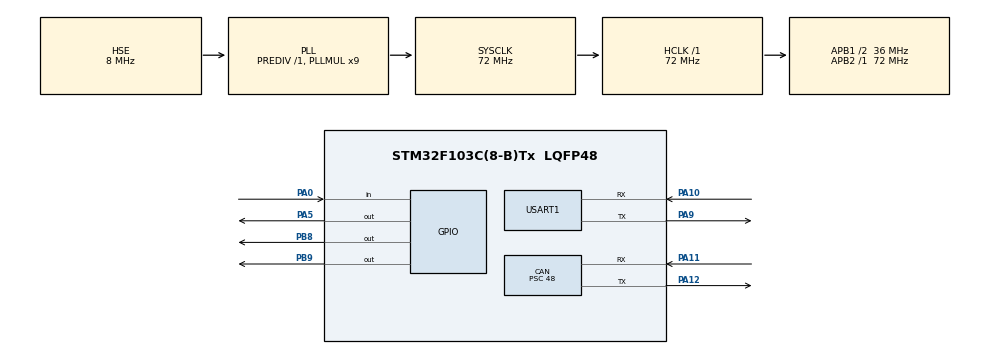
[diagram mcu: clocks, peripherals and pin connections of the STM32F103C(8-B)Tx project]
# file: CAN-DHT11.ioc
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CAN.BS1=CAN_BS1_2TQ
CAN.BS2=CAN_BS2_3TQ
CAN.CalculateBaudRate=124999
CAN.CalculateTimeBit=8000
CAN.CalculateTimeQuantum=1333.3333333333335
CAN.Mode=CAN_MODE_LOOPBACK
CAN.Prescaler=48
FREERTOS.Queues01=OLEDQueue,2,DHT11_Data,0,Dynamic,NULL,NULL;CANQueue,5,Can_Data,0,Dynamic,NULL,NULL
FREERTOS.Tasks01=defaultTask,24,128,StartDefaultTask,Default,NULL,Dynamic,NULL,NULL;OLEDTask,8,128,OLEDStartTask,Default,NULL,Dynamic,NULL,NULL;DHT11Task,9,256,DHT11StartTask,Default,NULL,Dynamic,NULL,NULL;CANTask,11,256,CANStartTask,Default,NULL,Dynamic,NULL,NULL
FREERTOS.configTOTAL_HEAP_SIZE=5120
Mcu.Family=STM32F1
Mcu.Name=STM32F103C(8-B)Tx
Mcu.Package=LQFP48
NVIC.PriorityGroup=NVIC_PRIORITYGROUP_4
NVIC.TIM4_IRQn=true\:15\:0\:false\:false\:true\:false\:false\:true\:true
NVIC.TimeBase=TIM4_IRQn
NVIC.TimeBaseIP=TIM4
NVIC.USB_LP_CAN1_RX0_IRQn=true\:5\:0\:false\:false\:true\:true\:true\:true\:true
PA0-WKUP.GPIO_PuPd=GPIO_PULLUP
PA0-WKUP.Signal=GPIO_Input
PA10.Mode=Asynchronous
PA10.Signal=USART1_RX
PA11.Mode=CAN_Activate
PA11.Signal=CAN_RX
PA12.Mode=CAN_Activate
PA12.Signal=CAN_TX
PA13.Mode=Serial_Wire
PA13.Signal=SYS_JTMS-SWDIO
PA14.Mode=Serial_Wire
PA14.Signal=SYS_JTCK-SWCLK
PA5.Signal=GPIO_Output
PA9.Mode=Asynchronous
PA9.Signal=USART1_TX
PB8.GPIO_ModeDefaultOutputPP=GPIO_MODE_OUTPUT_OD
PB8.GPIO_PuPd=GPIO_NOPULL
PB8.Signal=GPIO_Output
PB9.Signal=GPIO_Output
PD0-OSC_IN.Mode=HSE-External-Oscillator
PD0-OSC_IN.Signal=RCC_OSC_IN
PD1-OSC_OUT.Mode=HSE-External-Oscillator
PD1-OSC_OUT.Signal=RCC_OSC_OUT
ProjectManager.HeapSize=0x200
ProjectManager.StackSize=0x400
ProjectManager.TargetToolchain=MDK-ARM V5.32
RCC.AHBFreq_Value=72000000
RCC.APB1CLKDivider=RCC_HCLK_DIV2
RCC.APB1Freq_Value=36000000
RCC.APB1TimFreq_Value=72000000
RCC.APB2Freq_Value=72000000
RCC.APB2TimFreq_Value=72000000
RCC.HCLKFreq_Value=72000000
RCC.PLLMUL=RCC_PLL_MUL9
RCC.PLLSourceVirtual=RCC_PLLSOURCE_HSE
RCC.SYSCLKFreq_VALUE=72000000
RCC.SYSCLKSource=RCC_SYSCLKSOURCE_PLLCLK
RCC.USBFreq_Value=72000000
TIM3.Prescaler=72-1
USART1.VirtualMode=VM_ASYNC
VP_FREERTOS_VS_CMSIS_V2.Mode=CMSIS_V2
VP_SYS_VS_tim4.Mode=TIM4
VP_TIM3_VS_ClockSourceINT.Mode=Internal
board=custom

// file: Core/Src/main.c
/* USER CODE BEGIN Header */
/**
  ******************************************************************************
  * @file           : main.c
  * @brief          : Main program body
  ******************************************************************************
  * @attention
  *
  * Copyright (c) 2025 STMicroelectronics.
  * All rights reserved.
  *
  * This software is licensed under terms that can be found in the LICENSE file
  * in the root directory of this software component.
  * If no LICENSE file comes with this software, it is provided AS-IS.
  *
  ******************************************************************************
  */
/* USER CODE END Header */
#include "main.h"
#include "cmsis_os.h"
#include "can.h"
#include "tim.h"
#include "usart.h"
#include "gpio.h"

void SystemClock_Config(void);
void MX_FREERTOS_Init(void);

int main(void)
{

  /* MCU Configuration--------------------------------------------------------*/

  /* Reset of all peripherals, Initializes the Flash interface and the Systick. */
  HAL_Init();

  /* Configure the system clock */
  SystemClock_Config();

  /* Initialize all configured peripherals */
  MX_GPIO_Init();
  MX_CAN_Init();
  MX_TIM3_Init();
  MX_USART1_UART_Init();

  /* Init scheduler */
  osKernelInitialize();

  /* Call init function for freertos objects (in cmsis_os2.c) */
  MX_FREERTOS_Init();

  /* Start scheduler */
  osKernelStart();

  /* We should never get here as control is now taken by the scheduler */

  /* Infinite loop */
  while (1)
  {

  }
}

void SystemClock_Config(void)
{
  RCC_OscInitTypeDef RCC_OscInitStruct = {0};
  RCC_ClkInitTypeDef RCC_ClkInitStruct = {0};

  /** Initializes the RCC Oscillators according to the specified parameters
  * in the RCC_OscInitTypeDef structure.
  */
  RCC_OscInitStruct.OscillatorType = RCC_OSCILLATORTYPE_HSE;
  RCC_OscInitStruct.HSEState = RCC_HSE_ON;
  RCC_OscInitStruct.HSEPredivValue = RCC_HSE_PREDIV_DIV1;
  RCC_OscInitStruct.HSIState = RCC_HSI_ON;
  RCC_OscInitStruct.PLL.PLLState = RCC_PLL_ON;
  RCC_OscInitStruct.PLL.PLLSource = RCC_PLLSOURCE_HSE;
  RCC_OscInitStruct.PLL.PLLMUL = RCC_PLL_MUL9;
  if (HAL_RCC_OscConfig(&RCC_OscInitStruct) != HAL_OK)
  {
    Error_Handler();
  }

  /** Initializes the CPU, AHB and APB buses clocks
  */
  RCC_ClkInitStruct.ClockType = RCC_CLOCKTYPE_HCLK|RCC_CLOCKTYPE_SYSCLK
                              |RCC_CLOCKTYPE_PCLK1|RCC_CLOCKTYPE_PCLK2;
  RCC_ClkInitStruct.SYSCLKSource = RCC_SYSCLKSOURCE_PLLCLK;
  RCC_ClkInitStruct.AHBCLKDivider = RCC_SYSCLK_DIV1;
  RCC_ClkInitStruct.APB1CLKDivider = RCC_HCLK_DIV2;
  RCC_ClkInitStruct.APB2CLKDivider = RCC_HCLK_DIV1;

  if (HAL_RCC_ClockConfig(&RCC_ClkInitStruct, FLASH_LATENCY_2) != HAL_OK)
  {
    Error_Handler();
  }
}

void HAL_TIM_PeriodElapsedCallback(TIM_HandleTypeDef *htim)
{
  if (htim->Instance == TIM4)
  {
    HAL_IncTick();
  }
}

void Error_Handler(void)
{
  __disable_irq();
  while (1)
  {
  }
}

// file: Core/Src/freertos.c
/* USER CODE BEGIN Header */
/**
  ******************************************************************************
  * File Name          : freertos.c
  * Description        : Code for freertos applications
  ******************************************************************************
  * @attention
  *
  * Copyright (c) 2025 STMicroelectronics.
  * All rights reserved.
  *
  * This software is licensed under terms that can be found in the LICENSE file
  * in the root directory of this software component.
  * If no LICENSE file comes with this software, it is provided AS-IS.
  *
  ******************************************************************************
  */
/* USER CODE END Header */

#include "FreeRTOS.h"
#include "task.h"
#include "main.h"
#include "cmsis_os.h"

/* USER CODE BEGIN Includes */
#include "DHT11_task.h"
#include "OLED_task.h"
#include "CAN_Config.h"
#include "CAN_task.h"
/* USER CODE END Includes */

/* USER CODE BEGIN PM */
void HAL_CAN_RxFifo0MsgPendingCallback(CAN_HandleTypeDef *hcan) {
    CAN_ReceiveHandler(hcan);
}
/* USER CODE END PM */

/* Definitions for defaultTask */
osThreadId_t defaultTaskHandle;
const osThreadAttr_t defaultTask_attributes = {
  .name = "defaultTask",
  .stack_size = 128 * 4,
  .priority = (osPriority_t) osPriorityNormal,
};
/* Definitions for OLEDTask */
osThreadId_t OLEDTaskHandle;
const osThreadAttr_t OLEDTask_attributes = {
  .name = "OLEDTask",
  .stack_size = 128 * 4,
  .priority = (osPriority_t) osPriorityLow,
};
/* Definitions for DHT11Task */
osThreadId_t DHT11TaskHandle;
const osThreadAttr_t DHT11Task_attributes = {
  .name = "DHT11Task",
  .stack_size = 256 * 4,
  .priority = (osPriority_t) osPriorityLow1,
};
/* Definitions for CANTask */
osThreadId_t CANTaskHandle;
const osThreadAttr_t CANTask_attributes = {
  .name = "CANTask",
  .stack_size = 256 * 4,
  .priority = (osPriority_t) osPriorityLow3,
};
/* Definitions for OLEDQueue */
osMessageQueueId_t OLEDQueueHandle;
const osMessageQueueAttr_t OLEDQueue_attributes = {
  .name = "OLEDQueue"
};
/* Definitions for CANQueue */
osMessageQueueId_t CANQueueHandle;
const osMessageQueueAttr_t CANQueue_attributes = {
  .name = "CANQueue"
};

void StartDefaultTask(void *argument);
void OLEDStartTask(void *argument);
void DHT11StartTask(void *argument);
void CANStartTask(void *argument);

void MX_FREERTOS_Init(void); /* (MISRA C 2004 rule 8.1) */

void MX_FREERTOS_Init(void) {

  /* Create the queue(s) */
  /* creation of OLEDQueue */
  OLEDQueueHandle = osMessageQueueNew (2, sizeof(DHT11_Data), &OLEDQueue_attributes);

  /* creation of CANQueue */
  CANQueueHandle = osMessageQueueNew (5, sizeof(DHT11_Data), &CANQueue_attributes);

  /* Create the thread(s) */
  /* creation of defaultTask */
  defaultTaskHandle = osThreadNew(StartDefaultTask, NULL, &defaultTask_attributes);

  /* creation of OLEDTask */
  OLEDTaskHandle = osThreadNew(OLEDStartTask, NULL, &OLEDTask_attributes);

  /* creation of DHT11Task */
  DHT11TaskHandle = osThreadNew(DHT11StartTask, NULL, &DHT11Task_attributes);

  /* creation of CANTask */
  CANTaskHandle = osThreadNew(CANStartTask, NULL, &CANTask_attributes);

}

void StartDefaultTask(void *argument)
{
  for(;;)
  {
    osDelay(1);
  }
}

//void OLEDStartTask(void *argument)
//{
//  /* USER CODE BEGIN OLEDStartTask */
//  /* Infinite loop */
//  for(;;)
//  {
//    osDelay(1);
//  }
//  /* USER CODE END OLEDStartTask */
//}

///* USER CODE BEGIN Header_DHT11StartTask */
///**
//* @brief Function implementing the DHT11Task thread.
//* @param argument: Not used
//* @retval None
//*/
///* USER CODE END Header_DHT11StartTask */
//void DHT11StartTask(void *argument)
//{
//  /* USER CODE BEGIN DHT11StartTask */
//  /* Infinite loop */
//  for(;;)
//  {
//    osDelay(1);
//  }
//  /* USER CODE END DHT11StartTask */
//}

///* USER CODE BEGIN Header_CANStartTask */
///**
//* @brief Function implementing the CANTask thread.
//* @param argument: Not used
//* @retval None
//*/
///* USER CODE END Header_CANStartTask */
//void CANStartTask(void *argument)
//{
//  /* USER CODE BEGIN CANStartTask */
//  /* Infinite loop */
//  for(;;)
//  {
//    osDelay(1);
//  }
//  /* USER CODE END CANStartTask */
//}
